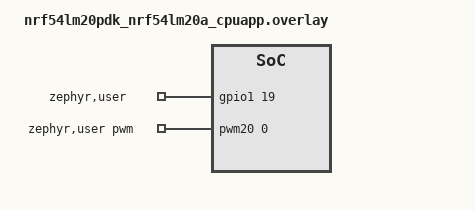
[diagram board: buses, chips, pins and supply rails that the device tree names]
/*
 * Copyright (c) 2025 Nordic Semiconductor ASA
 * SPDX-License-Identifier: LicenseRef-Nordic-5-Clause
 *
 * Test requires jumper between:
 *  - PWM20 OUT[0] at P1.29 <-> GPIO input at P1.19
 */

/ {
	zephyr,user {
		pwms = <&pwm20 0 160000 PWM_POLARITY_NORMAL>;
		gpios = <&gpio1 19 GPIO_ACTIVE_HIGH>;
	};
};
